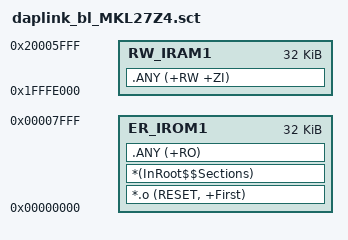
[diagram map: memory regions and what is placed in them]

LR_IROM1 0x00000000 0x8000  {    ; load region, size (32k)
  ER_IROM1 0x00000000 0x8000  {  ; load address = execution address
   *.o (RESET, +First)
   *(InRoot$$Sections)
   .ANY (+RO)
  }
  RW_IRAM1 0x1FFFE000 0x8000 {   ; RAM (32k)
   .ANY (+RW +ZI)
  }
}

